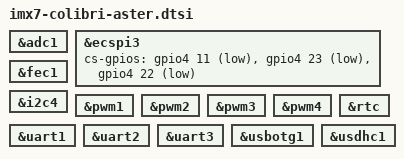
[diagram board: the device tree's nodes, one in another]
// SPDX-License-Identifier: GPL-2.0-or-later OR MIT
/*
 * Copyright 2017-2022 Toradex
 */

&adc1 {
	status = "okay";
};

/* Colibri SSP */
&ecspi3 {
	cs-gpios = <
		&gpio4 11 GPIO_ACTIVE_LOW /* SODIMM 86 / regular SSPFRM as UNO_SPI_CS or  */
		&gpio4 23 GPIO_ACTIVE_LOW /* SODIMM 65 / already muxed pinctrl_gpio2 as SPI_CE0_N */
		&gpio4 22 GPIO_ACTIVE_LOW /* SODIMM 85 / already muxed pinctrl_gpio2 as SPI_CE1_N */
	>;
	status = "okay";
};

&fec1 {
	status = "okay";
};

&i2c4 {
	status = "okay";
};

&pwm1 {
	status = "okay";
};

&pwm2 {
	status = "okay";
};

&pwm3 {
	status = "okay";
};

&pwm4 {
	status = "okay";
};

/* M41T0M6 real time clock */
&rtc {
	status = "okay";
};

&uart1 {
	status = "okay";
};

&uart2 {
	status = "okay";
};

&uart3 {
	status = "okay";
};

&usbotg1 {
	status = "okay";
};

/* Colibri MMC/SD */
&usdhc1 {
	status = "okay";
};
